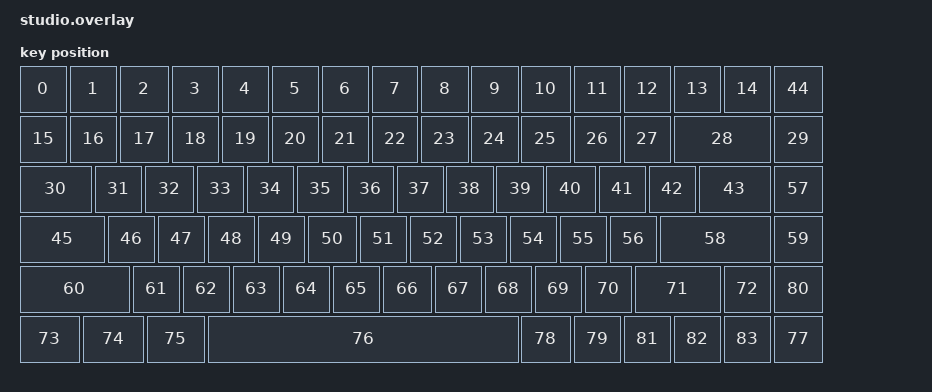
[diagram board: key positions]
/* Generated by tools/generate_edge_studio.py. */
#include <physical_layouts.dtsi>
/ {
 chosen { /delete-property/ zmk,matrix-transform;
          zmk,physical-layout = &edge_physical_layout;
          zmk,studio-rpc-uart = &edge_studio_uart; };
 edge_physical_layout: edge_physical_layout {
  compatible = "zmk,physical-layout"; display-name = "Lofree Edge 84";
  transform = <&edge_transform>; kscan = <&kscan0>;
  keys =
   <&key_physical_attrs 100 100 0 0 0 0 0>, /* position 0, slot 0: Esc */
   <&key_physical_attrs 100 100 100 0 0 0 0>, /* position 1, slot 1: F1 */
   <&key_physical_attrs 104 100 200 0 0 0 0>, /* position 2, slot 2: F2 */
   <&key_physical_attrs 100 100 304 0 0 0 0>, /* position 3, slot 3: F3 */
   <&key_physical_attrs 100 100 404 0 0 0 0>, /* position 4, slot 4: F4 */
   <&key_physical_attrs 100 100 504 0 0 0 0>, /* position 5, slot 5: F5 */
   <&key_physical_attrs 100 100 604 0 0 0 0>, /* position 6, slot 6: F6 */
   <&key_physical_attrs 100 100 704 0 0 0 0>, /* position 7, slot 7: F7 */
   <&key_physical_attrs 100 100 804 0 0 0 0>, /* position 8, slot 8: F8 */
   <&key_physical_attrs 100 100 904 0 0 0 0>, /* position 9, slot 9: F9 */
   <&key_physical_attrs 104 100 1004 0 0 0 0>, /* position 10, slot 10: F10 */
   <&key_physical_attrs 100 100 1108 0 0 0 0>, /* position 11, slot 11: F11 */
   <&key_physical_attrs 100 100 1208 0 0 0 0>, /* position 12, slot 12: F12 */
   <&key_physical_attrs 100 100 1308 0 0 0 0>, /* position 13, slot 13: PrintScreen */
   <&key_physical_attrs 100 100 1408 0 0 0 0>, /* position 14, slot 14: Insert */
   <&key_physical_attrs 100 100 0 100 0 0 0>, /* position 15, slot 15: ` */
   <&key_physical_attrs 100 100 100 100 0 0 0>, /* position 16, slot 16: 1 */
   <&key_physical_attrs 104 100 200 100 0 0 0>, /* position 17, slot 17: 2 */
   <&key_physical_attrs 100 100 304 100 0 0 0>, /* position 18, slot 18: 3 */
   <&key_physical_attrs 100 100 404 100 0 0 0>, /* position 19, slot 19: 4 */
   <&key_physical_attrs 100 100 504 100 0 0 0>, /* position 20, slot 20: 5 */
   <&key_physical_attrs 100 100 604 100 0 0 0>, /* position 21, slot 21: 6 */
   <&key_physical_attrs 100 100 704 100 0 0 0>, /* position 22, slot 22: 7 */
   <&key_physical_attrs 100 100 804 100 0 0 0>, /* position 23, slot 23: 8 */
   <&key_physical_attrs 100 100 904 100 0 0 0>, /* position 24, slot 24: 9 */
   <&key_physical_attrs 104 100 1004 100 0 0 0>, /* position 25, slot 25: 0 */
   <&key_physical_attrs 100 100 1108 100 0 0 0>, /* position 26, slot 26: - */
   <&key_physical_attrs 100 100 1208 100 0 0 0>, /* position 27, slot 27: + */
   <&key_physical_attrs 200 100 1308 100 0 0 0>, /* position 28, slot 28: BackSpace */
   <&key_physical_attrs 104 100 1508 100 0 0 0>, /* position 29, slot 29: Home */
   <&key_physical_attrs 150 100 0 200 0 0 0>, /* position 30, slot 30: Tab */
   <&key_physical_attrs 100 100 150 200 0 0 0>, /* position 31, slot 31: Q */
   <&key_physical_attrs 104 100 250 200 0 0 0>, /* position 32, slot 32: W */
   <&key_physical_attrs 100 100 354 200 0 0 0>, /* position 33, slot 33: E */
   <&key_physical_attrs 100 100 454 200 0 0 0>, /* position 34, slot 34: R */
   <&key_physical_attrs 100 100 554 200 0 0 0>, /* position 35, slot 35: T */
   <&key_physical_attrs 100 100 654 200 0 0 0>, /* position 36, slot 36: Y */
   <&key_physical_attrs 100 100 754 200 0 0 0>, /* position 37, slot 37: U */
   <&key_physical_attrs 100 100 854 200 0 0 0>, /* position 38, slot 38: I */
   <&key_physical_attrs 100 100 954 200 0 0 0>, /* position 39, slot 39: O */
   <&key_physical_attrs 104 100 1054 200 0 0 0>, /* position 40, slot 40: P */
   <&key_physical_attrs 100 100 1158 200 0 0 0>, /* position 41, slot 41: [ */
   <&key_physical_attrs 100 100 1258 200 0 0 0>, /* position 42, slot 42: ] */
   <&key_physical_attrs 150 100 1358 200 0 0 0>, /* position 43, slot 43: \ */
   <&key_physical_attrs 104 100 1508 0 0 0 0>, /* position 44, slot 44: Delete */
   <&key_physical_attrs 177 100 0 300 0 0 0>, /* position 45, slot 45: CapsLock */
   <&key_physical_attrs 100 100 177 300 0 0 0>, /* position 46, slot 46: A */
   <&key_physical_attrs 100 100 277 300 0 0 0>, /* position 47, slot 47: S */
   <&key_physical_attrs 100 100 377 300 0 0 0>, /* position 48, slot 48: D */
   <&key_physical_attrs 100 100 477 300 0 0 0>, /* position 49, slot 49: F */
   <&key_physical_attrs 104 100 577 300 0 0 0>, /* position 50, slot 50: G */
   <&key_physical_attrs 100 100 681 300 0 0 0>, /* position 51, slot 51: H */
   <&key_physical_attrs 100 100 781 300 0 0 0>, /* position 52, slot 52: J */
   <&key_physical_attrs 100 100 881 300 0 0 0>, /* position 53, slot 53: K */
   <&key_physical_attrs 100 100 981 300 0 0 0>, /* position 54, slot 54: L */
   <&key_physical_attrs 100 100 1081 300 0 0 0>, /* position 55, slot 55: ; */
   <&key_physical_attrs 100 100 1181 300 0 0 0>, /* position 56, slot 56: ' */
   <&key_physical_attrs 104 100 1508 200 0 0 0>, /* position 57, slot 57: End */
   <&key_physical_attrs 227 100 1281 300 0 0 0>, /* position 58, slot 58: Enter */
   <&key_physical_attrs 104 100 1508 300 0 0 0>, /* position 59, slot 59: PageUp */
   <&key_physical_attrs 227 100 0 400 0 0 0>, /* position 60, slot 60: Left Shift */
   <&key_physical_attrs 100 100 227 400 0 0 0>, /* position 61, slot 62: Z */
   <&key_physical_attrs 100 100 327 400 0 0 0>, /* position 62, slot 63: X */
   <&key_physical_attrs 100 100 427 400 0 0 0>, /* position 63, slot 64: C */
   <&key_physical_attrs 100 100 527 400 0 0 0>, /* position 64, slot 65: V */
   <&key_physical_attrs 100 100 627 400 0 0 0>, /* position 65, slot 66: B */
   <&key_physical_attrs 104 100 727 400 0 0 0>, /* position 66, slot 67: N */
   <&key_physical_attrs 100 100 831 400 0 0 0>, /* position 67, slot 68: M */
   <&key_physical_attrs 100 100 931 400 0 0 0>, /* position 68, slot 69: , */
   <&key_physical_attrs 100 100 1031 400 0 0 0>, /* position 69, slot 70: . */
   <&key_physical_attrs 100 100 1131 400 0 0 0>, /* position 70, slot 71: / */
   <&key_physical_attrs 177 100 1231 400 0 0 0>, /* position 71, slot 73: Right Shift */
   <&key_physical_attrs 100 100 1408 400 0 0 0>, /* position 72, slot 74: Up */
   <&key_physical_attrs 127 100 0 500 0 0 0>, /* position 73, slot 75: Left Ctrl */
   <&key_physical_attrs 127 100 127 500 0 0 0>, /* position 74, slot 76: Left Win */
   <&key_physical_attrs 123 100 254 500 0 0 0>, /* position 75, slot 77: Left Alt */
   <&key_physical_attrs 627 100 377 500 0 0 0>, /* position 76, slot 80: Space */
   <&key_physical_attrs 104 100 1508 500 0 0 0>, /* position 77, slot 83: Right */
   <&key_physical_attrs 104 100 1004 500 0 0 0>, /* position 78, slot 84: Right Alt */
   <&key_physical_attrs 100 100 1108 500 0 0 0>, /* position 79, slot 85: Fn */
   <&key_physical_attrs 104 100 1508 400 0 0 0>, /* position 80, slot 86: PageDown */
   <&key_physical_attrs 100 100 1208 500 0 0 0>, /* position 81, slot 87: Right Ctrl */
   <&key_physical_attrs 100 100 1308 500 0 0 0>, /* position 82, slot 88: Left */
   <&key_physical_attrs 100 100 1408 500 0 0 0>; /* position 83, slot 89: Down */
 };
};
&usbd { edge_studio_uart: edge_studio_uart {
 compatible = "zephyr,cdc-acm-uart";
}; };
